VERSION ""

NS_ :

BS_:

BU_: TBox

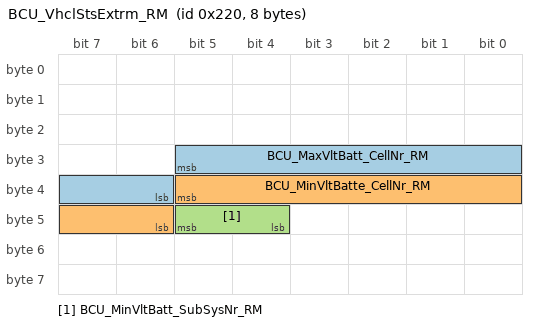
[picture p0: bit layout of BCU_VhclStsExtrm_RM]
BO_ 544 BCU_VhclStsExtrm_RM: 8 CGW
 SG_ BCU_MaxVltBatt_CellNr_RM : 29|8@0+ (1,0) [0|255] "" TBox
 SG_ BCU_MinVltBatte_CellNr_RM : 37|8@0+ (1,0) [0|255] "" TBox
 SG_ BCU_MinVltBatt_SubSysNr_RM : 45|2@0+ (1,0) [0|3] "" TBox

CM_ SG_ 544 BCU_MaxVltBatt_CellNr_RM "Number of max voltage cell
电压最大单体的编号";
CM_ SG_ 544 BCU_MinVltBatte_CellNr_RM "Number of max voltage cell
电压最小单体的编号";
CM_ SG_ 544 BCU_MinVltBatt_SubSysNr_RM "Battery subsysterm number of min voltage
电压最小单体对应的电池子系统编号";

BA_DEF_ BO_  "NmMessage" ENUM "No","Yes";
BA_DEF_ BO_  "GenMsgSendType" ENUM  "Cycle","CA","CE","Event","NotUsed","NotUsed","NotUsed","IfActive","NoMsgSendType","NotUsed";
BA_DEF_ BO_  "GenMsgCycleTime" INT 0 0;
BA_DEF_ SG_  "GenSigSendType" ENUM  "Cycle","OnChange","OnWrite","IfActive","OnChangeWithRepetition","OnWriteWithRepetition","IfActiveWithRepetition";
BA_DEF_ SG_  "GenSigStartValue" INT 0 0;
BA_DEF_ BO_  "GenMsgCycleTimeFast" INT 0 0;
BA_DEF_ BO_  "GenMsgNrOfRepetition" INT 0 0;
BA_DEF_ BO_  "GenMsgDelayTime" INT 0 0;
BA_DEF_ BO_  "VFrameFormat" ENUM  "StandardCAN","ExtendedCAN","reserved","reserved","reserved","reserved","reserved","reserved","reserved","reserved","reserved","reserved","reserved","reserved","StandardCAN_FD","ExtendedCAN_FD";
BA_DEF_ BO_  "GenMsgCycleTimeActive" INT 0 500;
BA_DEF_ BO_  "GenMsgStartDelayTime" INT 0 500;

BA_DEF_DEF_  "NmMessage" "No";
BA_DEF_DEF_  "GenMsgSendType" "Cycle";
BA_DEF_DEF_  "GenMsgCycleTime" 0;
BA_DEF_DEF_  "GenSigSendType" "Cycle";
BA_DEF_DEF_  "GenSigStartValue" 0;
BA_DEF_DEF_  "GenMsgCycleTimeFast" 0;
BA_DEF_DEF_  "GenMsgNrOfRepetition" 0;
BA_DEF_DEF_  "GenMsgDelayTime" 0;
BA_DEF_DEF_  "VFrameFormat" "StandardCAN";
BA_DEF_DEF_  "GenMsgCycleTimeActive" 100;
BA_DEF_DEF_  "GenMsgStartDelayTime" 200;
